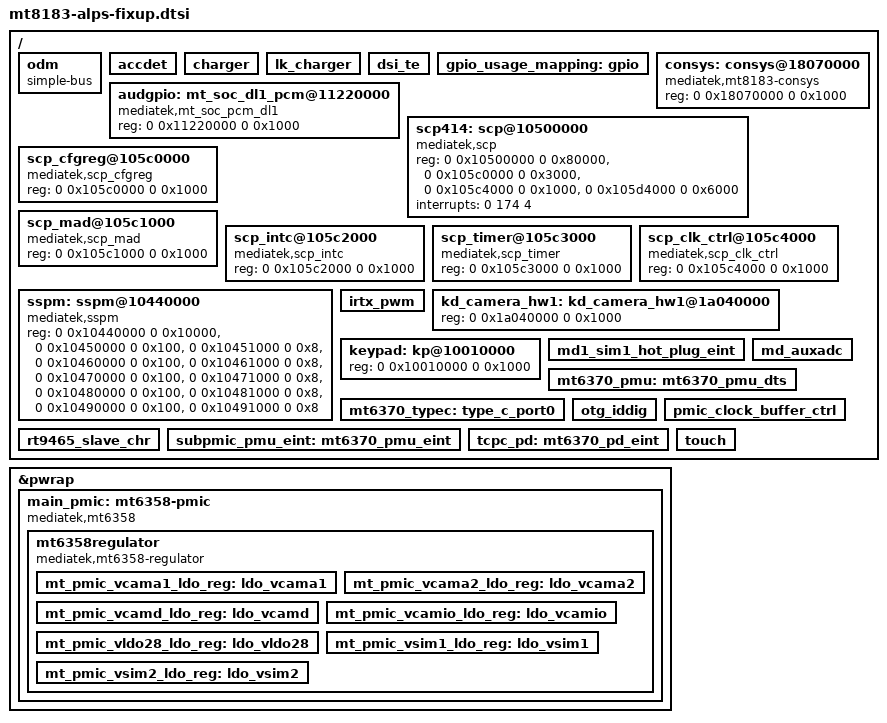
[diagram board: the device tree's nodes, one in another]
// SPDX-License-Identifier: (GPL-2.0 OR MIT)
/*
 * Minimal placeholder nodes required so the shipping (4.14-era) dtbo
 * overlay can resolve its __fixups__ during LK boot. These node paths and
 * labels mirror the 4.14 MT6771 DT. Real hardware configuration is
 * re-added on the 5.15 stack later; for now this only lets the kernel
 * get past LK's ufdt_overlay stage and boot.
 */

/ {
	odm: odm {
		compatible = "simple-bus";
		#address-cells = <1>;
		#size-cells = <1>;
	};

	accdet: accdet {
	};

	charger: charger {
	};

	lk_charger: lk_charger {
	};

	dsi_te: dsi_te {
	};

	gpio_usage_mapping: gpio {
	};

	audgpio: mt_soc_dl1_pcm@11220000 {
		compatible = "mediatek,mt_soc_pcm_dl1";
		reg = <0 0x11220000 0 0x1000>;
	};

	consys: consys@18070000 {
		compatible = "mediatek,mt8183-consys";
		reg = <0 0x18070000 0 0x1000>;
	};

	/* 4.14-style SCP node group: LK's platform_fdt_scp matches
	 * "mediatek,scp" exactly, so provide the legacy topology.
	 */
	scp414: scp@10500000 {
		compatible = "mediatek,scp";
		status = "okay";
		reg = <0 0x10500000 0 0x80000>,
		      <0 0x105c0000 0 0x3000>,
		      <0 0x105c4000 0 0x1000>,
		      <0 0x105d4000 0 0x6000>;
		interrupts = <0 174 4>;
	};

	scp_cfgreg@105c0000 {
		compatible = "mediatek,scp_cfgreg";
		reg = <0 0x105c0000 0 0x1000>;
	};

	scp_mad@105c1000 {
		compatible = "mediatek,scp_mad";
		reg = <0 0x105c1000 0 0x1000>;
	};

	scp_intc@105c2000 {
		compatible = "mediatek,scp_intc";
		reg = <0 0x105c2000 0 0x1000>;
	};

	scp_timer@105c3000 {
		compatible = "mediatek,scp_timer";
		reg = <0 0x105c3000 0 0x1000>;
	};

	scp_clk_ctrl@105c4000 {
		compatible = "mediatek,scp_clk_ctrl";
		reg = <0 0x105c4000 0 0x1000>;
	};

	sspm: sspm@10440000 {
		compatible = "mediatek,sspm";
		reg = <0 0x10440000 0 0x10000>,
		      <0 0x10450000 0 0x100>,
		      <0 0x10451000 0 0x8>,
		      <0 0x10460000 0 0x100>,
		      <0 0x10461000 0 0x8>,
		      <0 0x10470000 0 0x100>,
		      <0 0x10471000 0 0x8>,
		      <0 0x10480000 0 0x100>,
		      <0 0x10481000 0 0x8>,
		      <0 0x10490000 0 0x100>,
		      <0 0x10491000 0 0x8>;
	};

	irtx_pwm: irtx_pwm {
	};

	kd_camera_hw1: kd_camera_hw1@1a040000 {
		reg = <0 0x1a040000 0 0x1000>;
	};

	keypad: kp@10010000 {
		reg = <0 0x10010000 0 0x1000>;
	};

	md1_sim1_hot_plug_eint: md1_sim1_hot_plug_eint {
	};

	md_auxadc: md_auxadc {
	};

	mt6370_pmu: mt6370_pmu_dts {
	};

	mt6370_typec: type_c_port0 {
	};

	otg_iddig: otg_iddig {
	};

	pmic_clock_buffer_ctrl: pmic_clock_buffer_ctrl {
	};

	rt9465_slave_chr: rt9465_slave_chr {
	};

	subpmic_pmu_eint: mt6370_pmu_eint {
	};

	tcpc_pd: mt6370_pd_eint {
	};

	touch: touch {
	};
};

&pwrap {
	main_pmic: mt6358-pmic {
		compatible = "mediatek,mt6358";

		mt6358regulator {
			compatible = "mediatek,mt6358-regulator";

			mt_pmic_vcama1_ldo_reg: ldo_vcama1 {
			};
			mt_pmic_vcama2_ldo_reg: ldo_vcama2 {
			};
			mt_pmic_vcamd_ldo_reg: ldo_vcamd {
			};
			mt_pmic_vcamio_ldo_reg: ldo_vcamio {
			};
			mt_pmic_vldo28_ldo_reg: ldo_vldo28 {
			};
			mt_pmic_vsim1_ldo_reg: ldo_vsim1 {
			};
			mt_pmic_vsim2_ldo_reg: ldo_vsim2 {
			};
		};
	};
};
